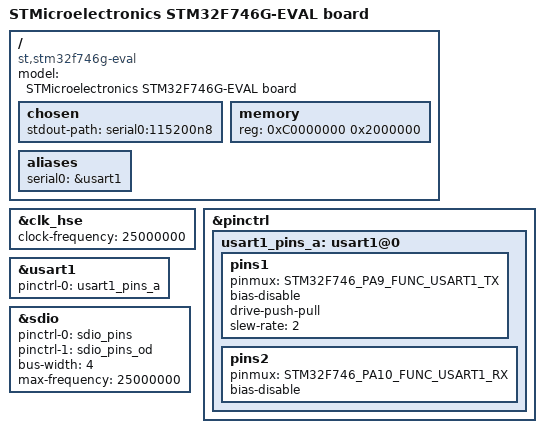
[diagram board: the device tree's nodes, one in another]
/*
 * Copyright 2018 - Christophe Priouzeau <christophe.priouzeau@st.com>
 *
 * Based on:
 * stm32f746-disco.dts from U-boot 2018.01
 * Copyright 2016 - Lee Jones <lee.jones@linaro.org>
 *
 * This file is dual-licensed: you can use it either under the terms
 * of the GPL or the X11 license, at your option. Note that this dual
 * licensing only applies to this file, and not this project as a
 * whole.
 *
 *  a) This file is free software; you can redistribute it and/or
 *     modify it under the terms of the GNU General Public License as
 *     published by the Free Software Foundation; either version 2 of the
 *     License, or (at your option) any later version.
 *
 *     This file is distributed in the hope that it will be useful,
 *     but WITHOUT ANY WARRANTY; without even the implied warranty of
 *     MERCHANTABILITY or FITNESS FOR A PARTICULAR PURPOSE.  See the
 *     GNU General Public License for more details.
 *
 * Or, alternatively,
 *
 *  b) Permission is hereby granted, free of charge, to any person
 *     obtaining a copy of this software and associated documentation
 *     files (the "Software"), to deal in the Software without
 *     restriction, including without limitation the rights to use,
 *     copy, modify, merge, publish, distribute, sublicense, and/or
 *     sell copies of the Software, and to permit persons to whom the
 *     Software is furnished to do so, subject to the following
 *     conditions:
 *
 *     The above copyright notice and this permission notice shall be
 *     included in all copies or substantial portions of the Software.
 *
 *     THE SOFTWARE IS PROVIDED "AS IS", WITHOUT WARRANTY OF ANY KIND,
 *     EXPRESS OR IMPLIED, INCLUDING BUT NOT LIMITED TO THE WARRANTIES
 *     OF MERCHANTABILITY, FITNESS FOR A PARTICULAR PURPOSE AND
 *     NONINFRINGEMENT. IN NO EVENT SHALL THE AUTHORS OR COPYRIGHT
 *     HOLDERS BE LIABLE FOR ANY CLAIM, DAMAGES OR OTHER LIABILITY,
 *     WHETHER IN AN ACTION OF CONTRACT, TORT OR OTHERWISE, ARISING
 *     FROM, OUT OF OR IN CONNECTION WITH THE SOFTWARE OR THE USE OR
 *     OTHER DEALINGS IN THE SOFTWARE.
 */

/dts-v1/;
#include "stm32f746.dtsi"
#include <dt-bindings/memory/stm32-sdram.h>

/ {
	model = "STMicroelectronics STM32F746G-EVAL board";
	compatible = "st,stm32f746g-eval", "st,stm32f746";

	chosen {
		stdout-path = "serial0:115200n8";
	};

	memory {
		reg = <0xC0000000 0x2000000>;
	};

	aliases {
		serial0 = &usart1;
	};
};

&clk_hse {
	clock-frequency = <25000000>;
};

&pinctrl {
	usart1_pins_a: usart1@0	{
		pins1 {
			pinmux = <STM32F746_PA9_FUNC_USART1_TX>;
				bias-disable;
				drive-push-pull;
				slew-rate = <2>;
		};
		pins2 {
			pinmux = <STM32F746_PA10_FUNC_USART1_RX>;
			bias-disable;
		};
	};
};

&usart1 {
	pinctrl-0 = <&usart1_pins_a>;
	pinctrl-names = "default";
	status = "okay";
};

&sdio {
	status = "okay";
	pinctrl-names = "default", "opendrain";
	pinctrl-0 = <&sdio_pins>;
	pinctrl-1 = <&sdio_pins_od>;
	bus-width = <4>;
	max-frequency = <25000000>;
};
